# HWSEQ register map
Vendor: Texas Instruments
Peripheral module from a debugger description file (folder DRA74xP_75xP_76xP_77xP).
Registers are 32-bit, access per field, reset 0x0 unless marked. A register's access mark holds for its fields unless they carry their own. Offsets are as the file gives them; lines under a group give offsets from that group; [hi:lo] are bit positions; {n}, {i} and the like mark numbered series; 'fields as' and 'values as' point back to an identical list; <NAME> marks a mode.

## HWSEQ
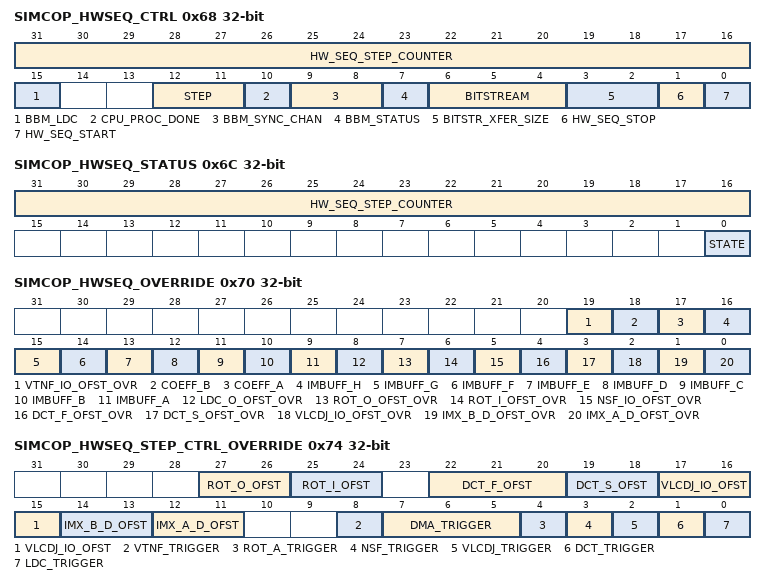
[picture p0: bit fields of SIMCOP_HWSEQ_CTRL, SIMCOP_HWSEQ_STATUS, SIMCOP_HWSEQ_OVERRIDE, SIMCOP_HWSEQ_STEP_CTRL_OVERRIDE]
0x68 SIMCOP_HWSEQ_CTRL — SIMCOP HW sequencer control register
  [31:16] HW_SEQ_STEP_COUNTER rw — Number of steps executed by the HW sequencer. HW_SEQ_STEP_COUNTER=0 corresponds to manual sequencing.
  [15] BBM_LDC rw — This bit field is reserved and users should write the reset value to this bit location. Choses if the automatic BBM interface is connected to VLCDJ or LDC (for SCS data). This register shall only be modified when there's no active traffic between VLCDJ/LDC and the BITSTREAM buffer
    0=VLCDJ; 1=LCD
  [12:11] STEP rw — This register is automatically updated by the HW sequencer when it is active. Otherwise, SW could use it to activate the content of a given set of step registers (SIMCOP_HWSEQ_STEP_*) or to chose the 1st step number of a sequence.
  [10] CPU_PROC_DONE wo — Used by the CPU to tell that it has completed data processing. This feature should be used together with the CPU_PROC_START_IRQ event Read's always return 0.
    0=ZERO (No effect.); 1=ONE (CPU processing completed.)
  [9:8] BBM_SYNC_CHAN rw — This bit field is reserved and users should write the reset value to this bit location. Defines the SIMCOP DMA HW synchronization channel to be used for BBM. This register is only used when BITSTREAM=ENCODE or DECODE. SW must ensure that the same DMA HW synchronization channel isn't used by the HW sequencer.
  [7] BBM_STATUS ro — This bit field is reserved and users should write the reset value to this bit location. Status of the Bitstream Buffer Management HW. Used only during automatic mode [BITSTREAM=5 or 6] Equals 0 (IDLE) in manual mode [BITSTREAM=0..4]. Set when automatic mode is entered. Automatic encode mode: used to detect when all banks have been flushed after the processing has completed (i.e. but request bank signals have been de-asserted by BBM). Automatic decode mode (BITSTREAM=DECODE): returns to 0 (IDLE) when automatic mode is left (BITSTREAM=COPR).
    0=IDLE (BBM is idle); 1=BUSY (BBM is busy.)
  [6:4] BITSTREAM rw — This bit field is reserved and users should write the reset value to this bit location. BITSTREAM buffer access control
    6=PINGPONG_DECODE (The BITSTREAM buffer is managed by HW as a PING/PONG buffer to support JPEG decode use case. It could be accessed by the SIMCOP DMA or the the VLCDJ module. The BITSTREAM HW sequence is reset when the mode is changed to COPR, VLCDJ or DMA.); 1=DMA_DMA (Bank 0: DMA (0x1000-0x17FF) Bank 1: DMA (0x1800-0x1FFF)); 0=COPR (Bank 0: coprocessor bus (0x1000-0x17FF) Bank 1: coprocessor bus (0x1800-0x1FFF)); 2=VLCDJ_VLCDJ (Bank 0: VLCDJ.B / LDC (0x000-0x7FF) Bank 1: VLCDJ.B / LDC (0x800-0xFFF)); 4=VLCDJ_DMA (Bank 0: VLCDJ.B / LDC (0x000-0x7FF) Bank 1: DMA (0x1800-0x1FFF)); 5=PINGPONG_ENCODE (The BITSTREAM buffer is managed by HW as a PING/PONG buffer to support JPEG encode / SCS use case. It could be accessed by the SIMCOP DMA or the the VLCDJ / LDC module. The BITSTREAM HW sequence is reset when the mode is changed to COPR, VLCDJ or DMA. This mode shall not be used when BBM / LDC =1); 3=DMA_VLCDJ (Bank 0: DMA (0x1000-0x17FF) Bank 1: VLCDJ.B / LDC (0x800-0xFFF))
  [3:2] BITSTR_XFER_SIZE rw — This bit field is reserved and users should write the reset value to this bit location. Defines the amount of data to be transferred per HW request to the SIMCOP DMA. Bigger sizes lead to better SDRAM efficiency but prevents fine grained DMA transfer arbitration. This register is only used by HW when BITSTREAM=ENCODE or BITSTREAM=DECODE.
    0=B2046 (2048 bytes); 1=B1024 (1024 bytes); 3=B256 (256 bytes); 2=B512 (512 bytes)
  [1] HW_SEQ_STOP wo — Stop the HW sequencer. This feature is typically used to recover from an error condition. Read's always return 0.
    0=NOEFFECT; 1=STOP (Stop the HW sequence immediately (dont wait for expected DONE events). Setting this bit while the sequencer is idle has no effect.)
  [0] HW_SEQ_START wo — Start the HW sequencer. Read's always return 0.
    0=NOCHANGE (No effect.); 1=START (Starts step number.STEP of the HW sequence. Setting this bit while the sequencer is running has no effect.)
0x6C SIMCOP_HWSEQ_STATUS ro — HW sequencer status register
  [31:16] HW_SEQ_STEP_COUNTER — Current step number
  [0] STATE — Current state
    0=IDLE; 1=RUNNING
0x70 SIMCOP_HWSEQ_OVERRIDE — HW sequencer override control register. Bits in this register select what configuration register control a resource. 0: Resource controlled by HW sequencer. HW uses the value from SIMCOP_HWSEQ_STEP_xx registers for the chosen resource 1: Resource controlled by SW HW uses the value from SIMCOP_HWSEQ_STEP_xx_OVERRIDE registers for the chosen resource The bit field name matches the one of the resource. For example, IMX_A_D_OFST_OVR selects if SIMCOP_HWSEQ_STEP_CTRL__x.IMX_A_D_OFST or.IMX_A_D_OFST controls how image buffers are arranged in the IMX #A address map.
  [19] VTNF_IO_OFST_OVR rw
  [18] COEFF_B rw — This bit field is reserved and users should write the reset value to this bit location.
  [17] COEFF_A rw — This bit field is reserved and users should write the reset value to this bit location.
  [16] IMBUFF_H rw
  [15] IMBUFF_G rw
  [14] IMBUFF_F rw
  [13] IMBUFF_E rw
  [12] IMBUFF_D rw — This bit field is reserved and users should write the reset value to this bit location.
  [11] IMBUFF_C rw — This bit field is reserved and users should write the reset value to this bit location.
  [10] IMBUFF_B rw — This bit field is reserved and users should write the reset value to this bit location.
  [9] IMBUFF_A rw — This bit field is reserved and users should write the reset value to this bit location.
  [8] LDC_O_OFST_OVR rw
  [7] ROT_O_OFST_OVR rw — This bit field is reserved and users should write the reset value to this bit location.
  [6] ROT_I_OFST_OVR rw — This bit field is reserved and users should write the reset value to this bit location.
  [5] NSF_IO_OFST_OVR rw — This bit field is reserved and users should write the reset value to this bit location.
  [4] DCT_F_OFST_OVR rw — This bit field is reserved and users should write the reset value to this bit location.
  [3] DCT_S_OFST_OVR rw — This bit field is reserved and users should write the reset value to this bit location.
  [2] VLCDJ_IO_OFST_OVR rw — This bit field is reserved and users should write the reset value to this bit location.
  [1] IMX_B_D_OFST_OVR rw — This bit field is reserved and users should write the reset value to this bit location.
  [0] IMX_A_D_OFST_OVR rw — This bit field is reserved and users should write the reset value to this bit location.
0x74 SIMCOP_HWSEQ_STEP_CTRL_OVERRIDE — HW sequencer override register. Used to execute SW sequences in parallel to HW sequencing steps
  [27:26] ROT_O_OFST rw — This bit field is reserved and users should write the reset value to this bit location. Controls ROT.O bus mapping to image buffers: 0x0000 0x1000 0x2000 0x3000
    0=ZERO (EFGH); 1=ONE (FGHE); 3=THREE (HEFG); 2=TWO (GHEF)
  [25:24] ROT_I_OFST rw — This bit field is reserved and users should write the reset value to this bit location. Controls ROT_I bus mapping to image buffers: 0x0000 0x1000 0x2000 0x3000
    0=ZERO (ABCD); 1=ONE (BCDA); 3=THREE (DABC); 2=TWO (CDAB)
  [22:20] DCT_F_OFST rw — This bit field is reserved and users should write the reset value to this bit location. Controls DCT.F bus mapping to image buffers: 0x0000 0x1000 0x2000 0x3000
    1=ONE (BCDG); 0=ZERO (ABCD); 2=TWO (CDGH); 4=FOUR (GHAB); 5=FIVE (HABC); 3=THREE (DGHA)
  [19:18] DCT_S_OFST rw — This bit field is reserved and users should write the reset value to this bit location. Controls DCT.S bus mapping to image buffers: 0x0000 0x1000
    0=ZERO (EF); 1=ONE (FG); 3=THREE (HE); 2=TWO (GH)
  [17:15] VLCDJ_IO_OFST rw — This bit field is reserved and users should write the reset value to this bit location. Controls VLCDJ IO data bus mapping to image buffers: 0x0000 0x1000 0x2000 0x3000
    values as DCT_F_OFST
  [14:13] IMX_B_D_OFST rw — This bit field is reserved and users should write the reset value to this bit location. Controls IMX #B data bus mapping to image buffers: 0x0000 0x1000 0x2000 0x3000
    0=ZERO (ABCD); 1=ONE (CDEF); 3=THREE (GHAB); 2=TWO (EFGH)
  [12:11] IMX_A_D_OFST rw — This bit field is reserved and users should write the reset value to this bit location. Controls IMX #A data bus mapping to image buffers: 0x0000 0x1000 0x2000 0x3000
    0=ZERO (ABCD); 1=ONE (CDEF); 3=THREE (GHAB); 2=TWO (EFGH)
  [8] VTNF_TRIGGER rw — SW controlled START/DONE synchronization
    0=WZERO (No Effect); 1=WONE (Send a start pulse and clears the memorized done pulse)
  [7:5] DMA_TRIGGER rw — SW controlled START/DONE synchronization
    {v}=CHAN{v-4} (Trigger channel {v-4}. Clears all memorized done pulses for DMA.) (v=4..7); 1=CHAN0_1 (Trigger channel 0 and 1. Clears all memorized done pulses for DMA.); 0=NE (No effect); 2=CHAN0_2 (Trigger channel 0, 1, 2. Clears all memorized done pulses for DMA.); 3=CHAN0_3 (Trigger channel 0, 1, 2 and 3. Clears all memorized done pulses for DMA.)
  [4] ROT_A_TRIGGER rw — This bit field is reserved and users should write the reset value to this bit location. SW controlled START/DONE synchronization
    values as VTNF_TRIGGER
  [3] NSF_TRIGGER rw — This bit field is reserved and users should write the reset value to this bit location. SW controlled START/DONE synchronization
    values as VTNF_TRIGGER
  [2] VLCDJ_TRIGGER rw — This bit field is reserved and users should write the reset value to this bit location. SW controlled START/DONE synchronization
    values as VTNF_TRIGGER
  [1] DCT_TRIGGER rw — This bit field is reserved and users should write the reset value to this bit location. SW controlled START/DONE synchronization
    values as VTNF_TRIGGER
  [0] LDC_TRIGGER rw — SW controlled START/DONE synchronization
    values as VTNF_TRIGGER
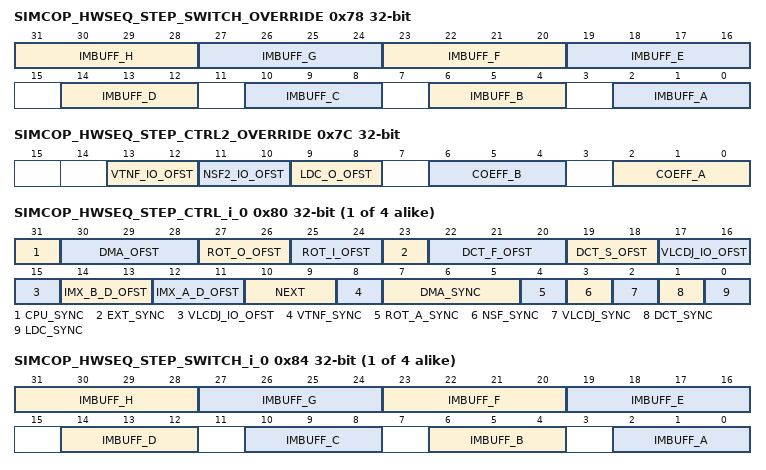
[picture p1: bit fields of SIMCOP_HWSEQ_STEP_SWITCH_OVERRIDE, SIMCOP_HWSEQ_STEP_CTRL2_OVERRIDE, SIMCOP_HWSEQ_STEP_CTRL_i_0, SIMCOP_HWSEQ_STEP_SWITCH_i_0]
0x78 SIMCOP_HWSEQ_STEP_SWITCH_OVERRIDE — HW sequencer override register. Used to execute SW sequences in parallel to HW sequencing steps
  [31:28] IMBUFF_H rw — Switch for image buffer #h
    0=COPR (Coprocessor bus); 1=DMA (SIMCOP DMA); 10=VTNF_IO; 9=LDC_O
  [27:24] IMBUFF_G rw — Switch for image buffer #g
    values as IMBUFF_H
  [23:20] IMBUFF_F rw — Switch for image buffer #f
    0=COPR (Coprocessor bus); 1=DMA (SIMCOP DMA); 8=VTNF_IO; 6=LDC_O
  [19:16] IMBUFF_E rw — Switch for image buffer #e
    values as IMBUFF_F
  [14:12] IMBUFF_D rw — This bit field is reserved and users should write the reset value to this bit location. Switch for image buffer #d
    6=ROT_A_I; 1=DMA (SIMCOP DMA); 7=RSV (Reserved); 0=COPR (Coprocessor bus); 2=IMX_A; 4=VLCDJ_IO; 5=DCT_F; 3=IMX_B
  [10:8] IMBUFF_C rw — This bit field is reserved and users should write the reset value to this bit location. Switch for image buffer #c.
    values as IMBUFF_D
  [6:4] IMBUFF_B rw — This bit field is reserved and users should write the reset value to this bit location. Switch for image buffer #b.
    6=ROT_A_I; 1=DMA (SIMCOP DMA); 7=RSV (Reserved); 0=COPR (Coprocessor bus); 2=IMX_A (IMX #A IMBUFF); 4=VLCDJ_IO; 5=DCT_F; 3=IMX_B (IMX #B IMBUFF)
  [2:0] IMBUFF_A rw — This bit field is reserved and users should write the reset value to this bit location. Switch for image buffer #a
    6=ROT_A_I; 1=DMA (SIMCOP DMA); 7=RSV (Reserved); 0=COPR (Coprocessor bus); 2=IMX_A (IMX #a IMBUFF); 4=VLCDJ_IO; 5=DCT_F; 3=IMX_B (IMX #B IMBUFF)
0x7C SIMCOP_HWSEQ_STEP_CTRL2_OVERRIDE — HW sequencer override register. Used to execute SW sequences in parallel to HW sequencing steps
  [13:12] VTNF_IO_OFST rw — Controls VTNF_IO bus mapping to image buffers: 0x0000 0x1000
    0=ZERO (EF); 1=ONE (FG); 3=E3 (HE); 2=E2 (GH)
  [11:10] NSF2_IO_OFST rw — This bit field is reserved and users should write the reset value to this bit location. Controls NSF_IO bus mapping to image buffers: 0x0000 0x1000
    0=ZERO (EF); 1=ONE (FG); 3=E3 (HE); 2=E2 (GH)
  [9:8] LDC_O_OFST rw — Controls LDC.O bus mapping to image buffers: 0x0000 0x1000 0x2000 0x3000
    0=E0 (EFGH); 1=E1 (FGHE); 3=E3 (HEFG); 2=E2 (GHEF)
  [6:4] COEFF_B rw — This bit field is reserved and users should write the reset value to this bit location. Coefficient buffer #B switch
    6=ROT_A_O; 1=DMA (SIMCOP DMA); 7=RSV (Reserved); 0=COPR (Coprocessor bus); 2=IMX_A; 4=VLCDJ_IO; 5=DCT_F; 3=IMX_B
  [2:0] COEFF_A rw — This bit field is reserved and users should write the reset value to this bit location. Coefficient buffer #a switch
    values as SIMCOP_HWSEQ_STEP_SWITCH_OVERRIDE.IMBUFF_D
{0x80+0x10*i} SIMCOP_HWSEQ_STEP_CTRL_i_{i} rw (i=0..3) — HW sequencer step control register
  [31] CPU_SYNC — Enable HW synchronization with the CPU so that it could be used for some processing on in the macro-block pipeline.
    0=DISABLED; 1=ENABLED
  [30:28] DMA_OFST — Controls DMA bus mapping to image buffers: 0x0000 0x1000 0x2000 0x3000 0x4000 0x5000 0x6000 0x7000
    6=SIX (GHABCDEF); 1=ONE (BCDEFGHA); 7=SEVEN (HABCDEFG); 0=ZERO (ABCDEFGH); 2=TWO (CDEFGHAB); 4=FOUR (EFGHABCD); 5=FIVE (FGHABCDE); 3=THREE (DEFGHABC)
  [27:26] ROT_O_OFST — This bit field is reserved and users should write the reset value to this bit location. Controls ROT.O bus mapping to image buffers: 0x0000 0x1000 0x2000 0x3000
    0=ZERO (EFGH); 1=ONE (FGHE); 3=THREE (HEFG); 2=TWO (GHEF)
  [25:24] ROT_I_OFST — This bit field is reserved and users should write the reset value to this bit location. Controls ROT_I bus mapping to image buffers: 0x0000 0x1000 0x2000 0x3000
    0=ZERO (ABCD); 1=ONE (BCDA); 3=THREE (DABC); 2=TWO (CDAB)
  [23] EXT_SYNC — The HW sequencer waits for an external start pulse i(START_STEP signal) n addition to internally selected synchronization events. DONE_STEP is always asserted when the step finishes regardless of this bit.
  [22:20] DCT_F_OFST — This bit field is reserved and users should write the reset value to this bit location. Controls DCT.F bus mapping to image buffers: 0x0000 0x1000 0x2000 0x3000
    values as SIMCOP_HWSEQ_STEP_CTRL_OVERRIDE.DCT_F_OFST
  [19:18] DCT_S_OFST — This bit field is reserved and users should write the reset value to this bit location. Controls DCT.S bus mapping to image buffers: 0x0000 0x1000
    0=ZERO (EF); 1=ONE (FG); 3=THREE (HE); 2=TWO (GH)
  [17:15] VLCDJ_IO_OFST — This bit field is reserved and users should write the reset value to this bit location. Controls VLCDJ IO data bus mapping to image buffers: 0x0000 0x1000 0x2000 0x3000
    values as SIMCOP_HWSEQ_STEP_CTRL_OVERRIDE.DCT_F_OFST
  [14:13] IMX_B_D_OFST — This bit field is reserved and users should write the reset value to this bit location. Controls IMX #B data bus mapping to image buffers: 0x0000 0x1000 0x2000 0x3000
    0=ZERO (ABCD); 1=ONE (CDEF); 3=THREE (GHAB); 2=TWO (EFGH)
  [12:11] IMX_A_D_OFST — This bit field is reserved and users should write the reset value to this bit location. Controls IMX #A data bus mapping to image buffers: 0x0000 0x1000 0x2000 0x3000
    0=ZERO (ABCD); 1=ONE (CDEF); 3=THREE (GHAB); 2=TWO (EFGH)
  [10:9] NEXT — Next channel in the sync chain
    {v}=STEP{v} (v=0..3)
  [8] VTNF_SYNC — Enable HW synchronization with the VTNF module
    0=DISABLED; 1=ENABLED
  [7:5] DMA_SYNC — Enable HW synchronization with the SIMCOP DMA
    {v}=CHAN{v-4} (Channel {v-4}) (v=4..7); 1=CHAN0_1 (Channel 0 and 1); 0=DISABLED; 2=CHAN0_2 (Channel 0, 1, 2); 3=CHAN0_3 (Channel 0, 1, 2 and 3)
  [4] ROT_A_SYNC — This bit field is reserved and users should write the reset value to this bit location. Enable HW synchronization with the ROT #a module
    0=DISABLED; 1=ENABLED
  [3] NSF_SYNC — This bit field is reserved and users should write the reset value to this bit location. Enable HW synchronization with the NSF module
    0=DISABLED; 1=ENABLED
  [2] VLCDJ_SYNC — This bit field is reserved and users should write the reset value to this bit location. Enable HW synchronization with the VLCDJ module
    0=DISABLED; 1=ENABLED
  [1] DCT_SYNC — Enable HW synchronization with the DCT module
    0=DISABLED; 1=ENABLED
  [0] LDC_SYNC — Enable HW synchronization with the LDC module
    0=DISABLED; 1=ENABLED
{0x84+0x10*i} SIMCOP_HWSEQ_STEP_SWITCH_i_{i} (i=0..3) — Image buffer switch control. The configuration of step #0 is used when HW sequencer is idle.
  [31:28] IMBUFF_H rw — Switch for image buffer #h
    6=DCT_F; 1=DMA (SIMCOP DMA); 7=ROT_A_O; 0=COPR (Coprocessor bus); 5=DCT_S; 10=VTNF_IO; 9=LDC_O; 4=VLCDJ_IO; 2=IMX_A; 8=NSF_IO; 3=IMX_B
  [27:24] IMBUFF_G rw — Switch for image buffer #g
    values as IMBUFF_H
  [23:20] IMBUFF_F rw — Switch for image buffer #f
    6=LDC_O; 1=DMA (SIMCOP DMA); 7=ROT_A_O; 0=COPR (Coprocessor bus); 2=IMX_A; 8=VTNF_IO; 4=DCT_S; 5=NSF_IO; 3=IMX_B
  [19:16] IMBUFF_E rw — Switch for image buffer #e
    values as IMBUFF_F
  [14:12] IMBUFF_D rw — This bit field is reserved and users should write the reset value to this bit location. Switch for image buffer #d
    values as SIMCOP_HWSEQ_STEP_SWITCH_OVERRIDE.IMBUFF_D
  [10:8] IMBUFF_C rw — This bit field is reserved and users should write the reset value to this bit location. Switch for image buffer #c.
    values as SIMCOP_HWSEQ_STEP_SWITCH_OVERRIDE.IMBUFF_D
  [6:4] IMBUFF_B rw — This bit field is reserved and users should write the reset value to this bit location. Switch for image buffer #b.
    values as SIMCOP_HWSEQ_STEP_SWITCH_OVERRIDE.IMBUFF_B
  [2:0] IMBUFF_A rw — This bit field is reserved and users should write the reset value to this bit location. Switch for image buffer #a
    values as SIMCOP_HWSEQ_STEP_SWITCH_OVERRIDE.IMBUFF_A
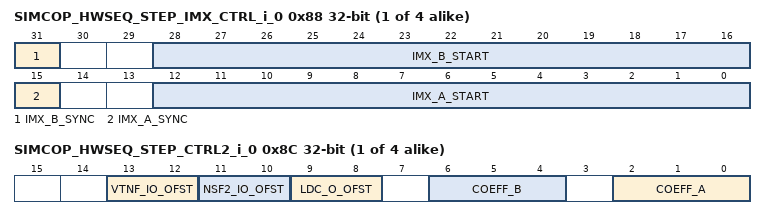
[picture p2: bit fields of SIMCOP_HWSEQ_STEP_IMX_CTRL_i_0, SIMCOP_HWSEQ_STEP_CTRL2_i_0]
{0x88+0x10*i} SIMCOP_HWSEQ_STEP_IMX_CTRL_i_{i} (i=0..3) — This register is reserved and users should write the reset value to this register location. HW sequencer step control register The configuration of step #0 is used when HW sequencer is idle.
  [31] IMX_B_SYNC rw — This bit field is reserved and users should write the reset value to this bit location. Enable HW synchronization with the iMX #b module
    0=DISABLED; 1=ENABLED
  [28:16] IMX_B_START rw — This bit field is reserved and users should write the reset value to this bit location. This register is only used when IMX_CTRL.IMX_B_SYNC=1. It contains the address, in 16-bit words, of the first instruction iMX will execute when it gets started.
  [15] IMX_A_SYNC rw — This bit field is reserved and users should write the reset value to this bit location. Enable HW synchronization with the IMX # a module
    0=DISABLED; 1=ENABLED
  [12:0] IMX_A_START rw — This bit field is reserved and users should write the reset value to this bit location. This register is only used when IMX_CTRL.IMX_A_SYNC=1. It contains the address, in 16-bit words, of the first instruction iMX will execute when it gets started.
{0x8C+0x10*i} SIMCOP_HWSEQ_STEP_CTRL2_i_{i} (i=0..3) — HW sequencer step control register
  fields as SIMCOP_HWSEQ_STEP_CTRL2_OVERRIDE
